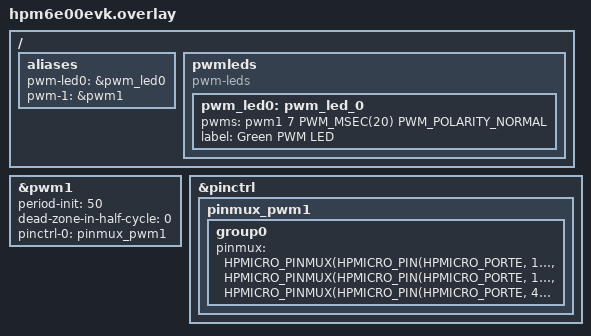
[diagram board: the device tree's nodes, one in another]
/*
 * Copyright 2025 HPMicro
 * SPDX-License-Identifier: Apache-2.0
 */


/ {
	aliases {
		pwm-led0 = &pwm_led0;
		pwm-1 = &pwm1;
	};

	pwmleds {
		compatible = "pwm-leds";
		pwm_led0: pwm_led_0 {
			pwms = <&pwm1 7 PWM_MSEC(20) PWM_POLARITY_NORMAL>;
			label = "Green PWM LED";
			status = "okay";
		};
	};
};

&pwm1 {
	status = "okay";
	period-init = <50>;
	dead-zone-in-half-cycle = <0>;
	pinctrl-0 = <&pinmux_pwm1>;
	pinctrl-names = "default";
};

&pinctrl {
		pinmux_pwm1: pinmux_pwm1 {
		group0 {
			pinmux = <HPMICRO_PINMUX(HPMICRO_PIN(HPMICRO_PORTE, 14), IOC_TYPE_IOC, 0, 16)>,
						<HPMICRO_PINMUX(HPMICRO_PIN(HPMICRO_PORTE, 15), IOC_TYPE_IOC, 0, 16)>,
						<HPMICRO_PINMUX(HPMICRO_PIN(HPMICRO_PORTE, 4), IOC_TYPE_IOC, 0, 16)>;
		};
	};
};

